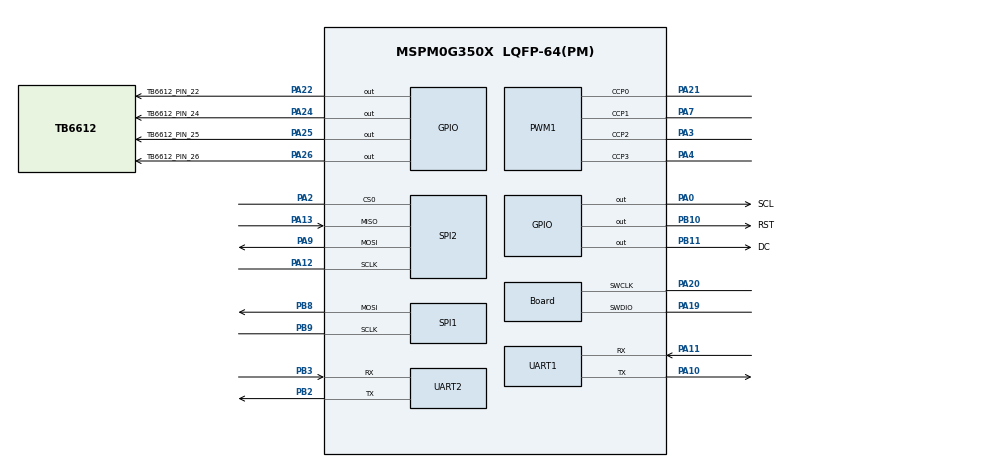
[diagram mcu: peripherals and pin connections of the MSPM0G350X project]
/**
 * @cliArgs --device "MSPM0G350X" --part "Default" --package "LQFP-64(PM)" --product "mspm0_sdk@2.02.00.05"
 * @versions {"tool":"1.21.1+3772"}
 */

/**
 * Import the modules used in this configuration.
 */
const ADC12         = scripting.addModule("/ti/driverlib/ADC12", {}, false);
const ADC121        = ADC12.addInstance();
const GPIO          = scripting.addModule("/ti/driverlib/GPIO", {}, false);
const GPIO1         = GPIO.addInstance();
const GPIO2         = GPIO.addInstance();
const GPIO3         = GPIO.addInstance();
const GPIO4         = GPIO.addInstance();
const GPIO5         = GPIO.addInstance();
const GPIO6         = GPIO.addInstance();
const GPIO7         = GPIO.addInstance();
const GPIO8         = GPIO.addInstance();
const GPIO9         = GPIO.addInstance();
const GPIO10        = GPIO.addInstance();
const GPIO11        = GPIO.addInstance();
const GPIO12        = GPIO.addInstance();
const GPIO13        = GPIO.addInstance();
const PWM           = scripting.addModule("/ti/driverlib/PWM", {}, false);
const PWM1          = PWM.addInstance();
const SPI           = scripting.addModule("/ti/driverlib/SPI", {}, false);
const SPI1          = SPI.addInstance();
const SPI2          = SPI.addInstance();
const SYSCTL        = scripting.addModule("/ti/driverlib/SYSCTL");
const SYSTICK       = scripting.addModule("/ti/driverlib/SYSTICK");
const TIMER         = scripting.addModule("/ti/driverlib/TIMER", {}, false);
const TIMER1        = TIMER.addInstance();
const TIMER2        = TIMER.addInstance();
const TIMER3        = TIMER.addInstance();
const UART          = scripting.addModule("/ti/driverlib/UART", {}, false);
const UART1         = UART.addInstance();
const UART2         = UART.addInstance();
const UART3         = UART.addInstance();
const ProjectConfig = scripting.addModule("/ti/project_config/ProjectConfig");

/**
 * Write custom configuration values to the imported modules.
 */
const divider7       = system.clockTree["PLL_PDIV"];
divider7.divideValue = 4;

const divider9       = system.clockTree["UDIV"];
divider9.divideValue = 2;

const gate7  = system.clockTree["MFCLKGATE"];
gate7.enable = true;

const multiplier2         = system.clockTree["PLL_QDIV"];
multiplier2.multiplyValue = 20;

const mux8       = system.clockTree["HSCLKMUX"];
mux8.inputSelect = "HSCLKMUX_SYSPLL0";

ADC121.$name                      = "ADC12_0";
ADC121.sampClkDiv                 = "DL_ADC12_CLOCK_DIVIDE_8";
ADC121.repeatMode                 = true;
ADC121.peripheral.adcPin0.$assign = "PA27";
ADC121.adcPin0Config.$name        = "ti_driverlib_gpio_GPIOPinGeneric15";

const Board                       = scripting.addModule("/ti/driverlib/Board", {}, false);
Board.peripheral.$assign          = "DEBUGSS";
Board.peripheral.swclkPin.$assign = "PA20";
Board.peripheral.swdioPin.$assign = "PA19";

GPIO1.$name                                       = "PORTB";
GPIO1.associatedPins.create(4);
GPIO1.associatedPins[0].$name                     = "RST";
GPIO1.associatedPins[0].pin.$assign               = "PB10";
GPIO1.associatedPins[1].$name                     = "DC";
GPIO1.associatedPins[1].pin.$assign               = "PB11";
GPIO1.associatedPins[2].$name                     = "CS";
GPIO1.associatedPins[2].pin.$assignAllowConflicts = "PB14";
GPIO1.associatedPins[3].$name                     = "BLK";
GPIO1.associatedPins[3].assignedPort              = "PORTB";
GPIO1.associatedPins[3].assignedPin               = "26";

GPIO2.$name                              = "GPIO_Key_up";
GPIO2.port                               = "PORTB";
GPIO2.associatedPins[0].$name            = "PIN_13";
GPIO2.associatedPins[0].direction        = "INPUT";
GPIO2.associatedPins[0].assignedPin      = "13";
GPIO2.associatedPins[0].internalResistor = "PULL_UP";

GPIO3.$name                              = "GPIO_Key_down";
GPIO3.port                               = "PORTB";
GPIO3.associatedPins[0].$name            = "PIN_19";
GPIO3.associatedPins[0].direction        = "INPUT";
GPIO3.associatedPins[0].internalResistor = "PULL_UP";
GPIO3.associatedPins[0].assignedPin      = "19";

GPIO4.$name                              = "GPIO_Key_left";
GPIO4.port                               = "PORTB";
GPIO4.associatedPins[0].direction        = "INPUT";
GPIO4.associatedPins[0].internalResistor = "PULL_UP";
GPIO4.associatedPins[0].$name            = "PIN_23";
GPIO4.associatedPins[0].assignedPin      = "23";

GPIO5.$name                              = "GPIO_Key_right";
GPIO5.port                               = "PORTB";
GPIO5.associatedPins[0].$name            = "PIN_18";
GPIO5.associatedPins[0].direction        = "INPUT";
GPIO5.associatedPins[0].assignedPin      = "18";
GPIO5.associatedPins[0].internalResistor = "PULL_UP";

GPIO6.$name                              = "GPIO_Key_medium";
GPIO6.port                               = "PORTB";
GPIO6.associatedPins[0].$name            = "PIN_24";
GPIO6.associatedPins[0].direction        = "INPUT";
GPIO6.associatedPins[0].assignedPin      = "24";
GPIO6.associatedPins[0].internalResistor = "PULL_UP";

GPIO7.$name                               = "GPIO_EXIT";
GPIO7.associatedPins.create(6);
GPIO7.associatedPins[0].$name             = "PIN_29";
GPIO7.associatedPins[0].direction         = "INPUT";
GPIO7.associatedPins[0].assignedPin       = "29";
GPIO7.associatedPins[0].interruptEn       = true;
GPIO7.associatedPins[0].interruptPriority = "1";
GPIO7.associatedPins[0].assignedPort      = "PORTA";
GPIO7.associatedPins[0].polarity          = "RISE_FALL";
GPIO7.associatedPins[1].$name             = "PIN_30";
GPIO7.associatedPins[1].assignedPin       = "30";
GPIO7.associatedPins[1].direction         = "INPUT";
GPIO7.associatedPins[1].interruptEn       = true;
GPIO7.associatedPins[1].interruptPriority = "1";
GPIO7.associatedPins[1].assignedPort      = "PORTA";
GPIO7.associatedPins[1].polarity          = "RISE_FALL";
GPIO7.associatedPins[2].$name             = "PIN_5";
GPIO7.associatedPins[2].assignedPin       = "5";
GPIO7.associatedPins[2].direction         = "INPUT";
GPIO7.associatedPins[2].interruptEn       = true;
GPIO7.associatedPins[2].interruptPriority = "1";
GPIO7.associatedPins[2].polarity          = "RISE_FALL";
GPIO7.associatedPins[2].assignedPort      = "PORTB";
GPIO7.associatedPins[3].$name             = "PIN_6";
GPIO7.associatedPins[3].assignedPin       = "6";
GPIO7.associatedPins[3].direction         = "INPUT";
GPIO7.associatedPins[3].interruptEn       = true;
GPIO7.associatedPins[3].interruptPriority = "1";
GPIO7.associatedPins[3].polarity          = "RISE_FALL";
GPIO7.associatedPins[3].assignedPort      = "PORTB";
GPIO7.associatedPins[4].$name             = "IMU_INT1";
GPIO7.associatedPins[4].assignedPort      = "PORTB";
GPIO7.associatedPins[4].assignedPin       = "7";
GPIO7.associatedPins[5].$name             = "IMU_INT2";
GPIO7.associatedPins[5].assignedPort      = "PORTB";
GPIO7.associatedPins[5].assignedPin       = "4";

GPIO8.$name                         = "GPIO_TB6612";
GPIO8.port                          = "PORTA";
GPIO8.associatedPins.create(4);
GPIO8.associatedPins[0].$name       = "TB6612_PIN_24";
GPIO8.associatedPins[0].assignedPin = "24";
GPIO8.associatedPins[0].pin.$assign = "PA24";
GPIO8.associatedPins[1].$name       = "TB6612_PIN_25";
GPIO8.associatedPins[1].assignedPin = "25";
GPIO8.associatedPins[1].pin.$assign = "PA25";
GPIO8.associatedPins[2].$name       = "TB6612_PIN_26";
GPIO8.associatedPins[2].assignedPin = "26";
GPIO8.associatedPins[2].pin.$assign = "PA26";
GPIO8.associatedPins[3].$name       = "TB6612_PIN_22";
GPIO8.associatedPins[3].assignedPin = "22";
GPIO8.associatedPins[3].pin.$assign = "PA22";

GPIO9.port                           = "PORTA";
GPIO9.$name                          = "GPIO";
GPIO9.associatedPins.create(2);
GPIO9.associatedPins[0].initialValue = "SET";
GPIO9.associatedPins[0].ioStructure  = "OD";
GPIO9.associatedPins[0].assignedPin  = "0";
GPIO9.associatedPins[0].$name        = "SCL";
GPIO9.associatedPins[0].pin.$assign  = "PA0";
GPIO9.associatedPins[1].initialValue = "SET";
GPIO9.associatedPins[1].ioStructure  = "OD";
GPIO9.associatedPins[1].assignedPin  = "1";
GPIO9.associatedPins[1].$name        = "SDA";

GPIO10.$name                              = "Tracking";
GPIO10.associatedPins.create(3);
GPIO10.associatedPins[0].assignedPort     = "PORTA";
GPIO10.associatedPins[0].internalResistor = "PULL_DOWN";
GPIO10.associatedPins[0].assignedPin      = "15";
GPIO10.associatedPins[0].$name            = "SO";
GPIO10.associatedPins[1].internalResistor = "PULL_DOWN";
GPIO10.associatedPins[1].assignedPort     = "PORTA";
GPIO10.associatedPins[1].assignedPin      = "28";
GPIO10.associatedPins[1].$name            = "S1";
GPIO10.associatedPins[2].internalResistor = "PULL_DOWN";
GPIO10.associatedPins[2].assignedPort     = "PORTB";
GPIO10.associatedPins[2].assignedPin      = "21";
GPIO10.associatedPins[2].$name            = "S2";

GPIO11.$name                          = "SPI_FOR_IMU_CS";
GPIO11.port                           = "PORTA";
GPIO11.associatedPins[0].$name        = "PIN_8";
GPIO11.associatedPins[0].initialValue = "SET";
GPIO11.associatedPins[0].ioStructure  = "SD";
GPIO11.associatedPins[0].assignedPin  = "8";

GPIO12.$name                          = "GPIO_BEEP";
GPIO12.associatedPins[0].$name        = "PIN_0";
GPIO12.associatedPins[0].assignedPort = "PORTB";
GPIO12.associatedPins[0].assignedPin  = "12";

GPIO13.$name                          = "LED";
GPIO13.associatedPins.create(2);
GPIO13.associatedPins[0].$name        = "LED_R";
GPIO13.associatedPins[0].assignedPort = "PORTB";
GPIO13.associatedPins[0].assignedPin  = "27";
GPIO13.associatedPins[1].$name        = "LED_B";
GPIO13.associatedPins[1].assignedPort = "PORTB";
GPIO13.associatedPins[1].assignedPin  = "16";

PWM1.$name                      = "PWM_0";
PWM1.ccIndex                    = [0,1,2,3];
PWM1.clockDivider               = 8;
PWM1.timerCount                 = 100;
PWM1.timerStartTimer            = true;
PWM1.clockPrescale              = 80;
PWM1.peripheral.$assign         = "TIMA0";
PWM1.peripheral.ccp0Pin.$assign = "PA21";
PWM1.peripheral.ccp1Pin.$assign = "PA7";
PWM1.peripheral.ccp2Pin.$assign = "PA3";
PWM1.peripheral.ccp3Pin.$assign = "PA4";
PWM1.PWM_CHANNEL_0.$name        = "ti_driverlib_pwm_PWMTimerCC0";
PWM1.PWM_CHANNEL_1.$name        = "ti_driverlib_pwm_PWMTimerCC1";
PWM1.ccp0PinConfig.$name        = "ti_driverlib_gpio_GPIOPinGeneric0";
PWM1.ccp1PinConfig.$name        = "ti_driverlib_gpio_GPIOPinGeneric1";
PWM1.PWM_CHANNEL_2.$name        = "ti_driverlib_pwm_PWMTimerCC2";
PWM1.PWM_CHANNEL_3.$name        = "ti_driverlib_pwm_PWMTimerCC3";
PWM1.ccp2PinConfig.$name        = "ti_driverlib_gpio_GPIOPinGeneric5";
PWM1.ccp3PinConfig.$name        = "ti_driverlib_gpio_GPIOPinGeneric6";

SPI1.$name                      = "SPI_0";
SPI1.targetBitRate              = 1000000;
SPI1.frameFormat                = "MOTO3";
SPI1.polarity                   = "1";
SPI1.phase                      = "1";
SPI1.direction                  = "PICO";
SPI1.peripheral.$assign         = "SPI1";
SPI1.peripheral.sclkPin.$assign = "PB9";
SPI1.peripheral.mosiPin.$assign = "PB8";
SPI1.sclkPinConfig.$name        = "ti_driverlib_gpio_GPIOPinGeneric2";
SPI1.mosiPinConfig.$name        = "ti_driverlib_gpio_GPIOPinGeneric3";

SPI2.$name                              = "SPI_FOR_IMU";
SPI2.spiClkSrc                          = "MFCLK";
SPI2.spiClkDiv                          = "8";
SPI2.targetBitRate                      = 5000000;
SPI2.calculatedBitRate                  = 1;
SPI2.peripheral.sclkPin.$assign         = "PA12";
SPI2.peripheral.mosiPin.$assign         = "PA9";
SPI2.peripheral.misoPin.$assign         = "PA13";
SPI2.peripheral.cs0Pin.$assign          = "PA2";
SPI2.sclkPinConfig.$name                = "ti_driverlib_gpio_GPIOPinGeneric7";
SPI2.sclkPinConfig.direction            = scripting.forceWrite("OUTPUT");
SPI2.sclkPinConfig.onlyInternalResistor = scripting.forceWrite(false);
SPI2.sclkPinConfig.passedPeripheralType = scripting.forceWrite("Digital");
SPI2.mosiPinConfig.$name                = "ti_driverlib_gpio_GPIOPinGeneric8";
SPI2.mosiPinConfig.direction            = scripting.forceWrite("OUTPUT");
SPI2.mosiPinConfig.hideOutputInversion  = scripting.forceWrite(false);
SPI2.mosiPinConfig.onlyInternalResistor = scripting.forceWrite(false);
SPI2.mosiPinConfig.passedPeripheralType = scripting.forceWrite("Digital");
SPI2.misoPinConfig.$name                = "ti_driverlib_gpio_GPIOPinGeneric9";
SPI2.misoPinConfig.onlyInternalResistor = scripting.forceWrite(false);
SPI2.misoPinConfig.passedPeripheralType = scripting.forceWrite("Digital");
SPI2.cs0PinConfig.$name                 = "ti_driverlib_gpio_GPIOPinGeneric10";
SPI2.cs0PinConfig.direction             = scripting.forceWrite("OUTPUT");
SPI2.cs0PinConfig.hideOutputInversion   = scripting.forceWrite(false);
SPI2.cs0PinConfig.onlyInternalResistor  = scripting.forceWrite(false);
SPI2.cs0PinConfig.passedPeripheralType  = scripting.forceWrite("Digital");

SYSCTL.clockTreeEn = true;

SYSTICK.periodEnable      = true;
SYSTICK.interruptEnable   = true;
SYSTICK.systickEnable     = true;
SYSTICK.period            = 80;
SYSTICK.interruptPriority = "2";

TIMER1.$name              = "TIMER_0";
TIMER1.timerClkPrescale   = 256;
TIMER1.interrupts         = ["ZERO"];
TIMER1.timerMode          = "PERIODIC";
TIMER1.timerPeriod        = "10ms";
TIMER1.interruptPriority  = "1";
TIMER1.peripheral.$assign = "TIMG0";

TIMER2.$name              = "TIMER_1";
TIMER2.timerClkPrescale   = 256;
TIMER2.timerPeriod        = "5ms";
TIMER2.timerMode          = "PERIODIC";
TIMER2.interrupts         = ["ZERO"];
TIMER2.interruptPriority  = "1";
TIMER2.peripheral.$assign = "TIMG6";

TIMER3.$name              = "TIMER_2";
TIMER3.timerClkPrescale   = 256;
TIMER3.timerMode          = "PERIODIC";
TIMER3.timerPeriod        = "10 ms";
TIMER3.interrupts         = ["ZERO"];
TIMER3.interruptPriority  = "2";
TIMER3.peripheral.$assign = "TIMG7";

UART1.$name                            = "UART_1";
UART1.targetBaudRate                   = 115200;
UART1.interruptPriority                = "2";
UART1.enabledInterrupts                = ["RX"];
UART1.peripheral.$assign               = "UART0";
UART1.peripheral.rxPin.$assign         = "PA11";
UART1.peripheral.txPin.$assign         = "PA10";
UART1.txPinConfig.$name                = "ti_driverlib_gpio_GPIOPinGeneric11";
UART1.txPinConfig.direction            = scripting.forceWrite("OUTPUT");
UART1.txPinConfig.hideOutputInversion  = scripting.forceWrite(false);
UART1.txPinConfig.onlyInternalResistor = scripting.forceWrite(false);
UART1.txPinConfig.passedPeripheralType = scripting.forceWrite("Digital");
UART1.rxPinConfig.$name                = "ti_driverlib_gpio_GPIOPinGeneric12";
UART1.rxPinConfig.hideOutputInversion  = scripting.forceWrite(false);
UART1.rxPinConfig.onlyInternalResistor = scripting.forceWrite(false);
UART1.rxPinConfig.passedPeripheralType = scripting.forceWrite("Digital");

UART2.$name                            = "UART_2";
UART2.targetBaudRate                   = 115200;
UART2.interruptPriority                = "0";
UART2.enabledInterrupts                = ["RX"];
UART2.peripheral.$assign               = "UART3";
UART2.peripheral.rxPin.$assign         = "PB3";
UART2.peripheral.txPin.$assign         = "PB2";
UART2.txPinConfig.$name                = "ti_driverlib_gpio_GPIOPinGeneric13";
UART2.txPinConfig.direction            = scripting.forceWrite("OUTPUT");
UART2.txPinConfig.hideOutputInversion  = scripting.forceWrite(false);
UART2.txPinConfig.onlyInternalResistor = scripting.forceWrite(false);
UART2.txPinConfig.passedPeripheralType = scripting.forceWrite("Digital");
UART2.rxPinConfig.$name                = "ti_driverlib_gpio_GPIOPinGeneric14";
UART2.rxPinConfig.hideOutputInversion  = scripting.forceWrite(false);
UART2.rxPinConfig.onlyInternalResistor = scripting.forceWrite(false);
UART2.rxPinConfig.passedPeripheralType = scripting.forceWrite("Digital");

UART3.$name                            = "UART_3";
UART3.targetBaudRate                   = 115200;
UART3.interruptPriority                = "2";
UART3.enabledInterrupts                = ["RX"];
UART3.txPinConfig.direction            = scripting.forceWrite("OUTPUT");
UART3.txPinConfig.hideOutputInversion  = scripting.forceWrite(false);
UART3.txPinConfig.onlyInternalResistor = scripting.forceWrite(false);
UART3.txPinConfig.passedPeripheralType = scripting.forceWrite("Digital");
UART3.txPinConfig.$name                = "ti_driverlib_gpio_GPIOPinGeneric16";
UART3.rxPinConfig.hideOutputInversion  = scripting.forceWrite(false);
UART3.rxPinConfig.onlyInternalResistor = scripting.forceWrite(false);
UART3.rxPinConfig.passedPeripheralType = scripting.forceWrite("Digital");
UART3.rxPinConfig.$name                = "ti_driverlib_gpio_GPIOPinGeneric17";

ProjectConfig.deviceSpin = "MSPM0G3507";

/**
 * Pinmux solution for unlocked pins/peripherals. This ensures that minor changes to the automatic solver in a future
 * version of the tool will not impact the pinmux you originally saw.  These lines can be completely deleted in order to
 * re-solve from scratch.
 */
ADC121.peripheral.$suggestSolution            = "ADC0";
GPIO1.associatedPins[3].pin.$suggestSolution  = "PB26";
GPIO2.associatedPins[0].pin.$suggestSolution  = "PB13";
GPIO3.associatedPins[0].pin.$suggestSolution  = "PB19";
GPIO4.associatedPins[0].pin.$suggestSolution  = "PB23";
GPIO5.associatedPins[0].pin.$suggestSolution  = "PB18";
GPIO6.associatedPins[0].pin.$suggestSolution  = "PB24";
GPIO7.associatedPins[0].pin.$suggestSolution  = "PA29";
GPIO7.associatedPins[1].pin.$suggestSolution  = "PA30";
GPIO7.associatedPins[2].pin.$suggestSolution  = "PB5";
GPIO7.associatedPins[3].pin.$suggestSolution  = "PB6";
GPIO7.associatedPins[4].pin.$suggestSolution  = "PB7";
GPIO7.associatedPins[5].pin.$suggestSolution  = "PB4";
GPIO9.associatedPins[1].pin.$suggestSolution  = "PA1";
GPIO10.associatedPins[0].pin.$suggestSolution = "PA15";
GPIO10.associatedPins[1].pin.$suggestSolution = "PA28";
GPIO10.associatedPins[2].pin.$suggestSolution = "PB21";
GPIO11.associatedPins[0].pin.$suggestSolution = "PA8";
GPIO12.associatedPins[0].pin.$suggestSolution = "PB12";
GPIO13.associatedPins[0].pin.$suggestSolution = "PB27";
GPIO13.associatedPins[1].pin.$suggestSolution = "PB16";
SPI2.peripheral.$suggestSolution              = "SPI0";
UART3.peripheral.$suggestSolution             = "UART1";
UART3.peripheral.rxPin.$suggestSolution       = "PA18";
UART3.peripheral.txPin.$suggestSolution       = "PA17";
